VERSION "Synthetic signal acceptance fixture - no production ECU"

NS_ :

BS_:

BU_: Tester ECU

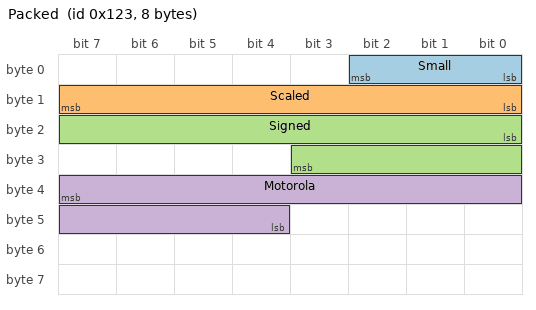
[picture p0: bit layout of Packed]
BO_ 291 Packed: 8 Tester
 SG_ Small : 0|3@1+ (1,0) [0|7] "" ECU
 SG_ Scaled : 8|8@1+ (0.1,0) [0|10] "V" ECU
 SG_ Signed : 16|12@1- (0.1,0) [-10|10] "A" ECU
 SG_ Motorola : 39|12@0+ (1,0) [0|4095] "" ECU

BO_ 2147483939 ExtendedSmall: 1 Tester
 SG_ Flag : 0|1@1+ (1,0) [0|1] "" ECU

BO_ 292 Full64: 8 Tester
 SG_ Wide : 0|64@1+ (1,0) [0|18446744073709551615] "" ECU

BO_ 293 Multiplexed: 3 Tester
 SG_ Selector M : 0|2@1+ (1,0) [0|3] "" ECU
 SG_ Branch0 m0 : 8|8@1+ (1,0) [0|255] "" ECU
 SG_ Branch1 m1 : 8|16@1+ (1,0) [0|65535] "" ECU

BO_ 294 FloatUnsupported: 4 ECU
 SG_ Float : 0|32@1+ (1,0) [0|1] "" Tester

CM_ BO_ 291 "SYNTHETIC: verifies bit layout, decimal truncation and initialization";
BA_DEF_ SG_ "GenSigStartValue" FLOAT 0 18446744073709551615;
BA_DEF_ BO_ "GenMsgCycleTime" INT 0 100000;
BA_DEF_DEF_ "GenMsgCycleTime" 10;
BA_ "GenSigStartValue" SG_ 291 Small 2;
BA_ "GenSigStartValue" SG_ 291 Scaled 12;
BA_ "GenSigStartValue" SG_ 293 Selector 0;
BA_ "GenSigStartValue" SG_ 293 Branch0 18;
BA_ "GenSigStartValue" SG_ 293 Branch1 4660;
VAL_ 291 Small 0 "Off" 2 "Ready" 7 "Invalid";
SIG_VALTYPE_ 294 Float : 1;
